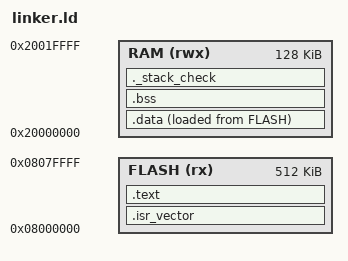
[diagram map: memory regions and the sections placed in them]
/* linker.ld - STM32F446RE: Flash 512K, SRAM 128K */
ENTRY(Reset_Handler)

MEMORY
{
  FLASH (rx)  : ORIGIN = 0x08000000, LENGTH = 512K
  RAM   (rwx) : ORIGIN = 0x20000000, LENGTH = 128K
}

_estack = ORIGIN(RAM) + LENGTH(RAM);
_Min_Stack_Size = 0x800;

SECTIONS
{
  .isr_vector :
  {
    . = ALIGN(4);
    KEEP(*(.isr_vector))
    . = ALIGN(4);
  } > FLASH

  .text :
  {
    . = ALIGN(4);
    *(.text*)
    *(.rodata*)
    . = ALIGN(4);
    _etext = .;
  } > FLASH

  _sidata = LOADADDR(.data);

  .data :
  {
    . = ALIGN(4);
    _sdata = .;
    *(.data*)
    . = ALIGN(4);
    _edata = .;
  } > RAM AT > FLASH

  .bss (NOLOAD) :
  {
    . = ALIGN(4);
    _sbss = .;
    *(.bss*)
    *(COMMON)
    . = ALIGN(4);
    _ebss = .;
  } > RAM

  /* Kiểm tra còn đủ chỗ cho stack, nếu không linker báo lỗi */
  ._stack_check (NOLOAD) :
  {
    . = ALIGN(8);
    . = . + _Min_Stack_Size;
  } > RAM
}
